# CY8C5888LTI_LP097 register map
File version: 0.1
Registers are 8-bit, read-write, no defined reset value unless marked. A register's access mark holds for its fields unless they carry their own. Offsets are from the block's base; [hi:lo] are bit positions; 'fields as' and 'values as' point back to an identical list.

## BLANK_TOGGLE
Base 0x00000000
0x40006578 BLANK_TOGGLE_CONTROL_REG

## CAM_SEL_REG
Base 0x00000000
0x40006579 CAM_SEL_REG_CONTROL_REG

## TRIG_CNT_RST
Base 0x00000000
0x40006470 TRIG_CNT_RST_CONTROL_REG

## TRG_CNT
Base 0x00000000
0x40006400 TRG_CNT_COUNTER 32-bit — UDB.A0 - Current Counter Value
0x40006420 TRG_CNT_PERIOD 32-bit — UDB.D0 - Assigned Period
0x40006430 TRG_CNT_COMPARE 32-bit — UDB.D1 - Assigned Compare Value
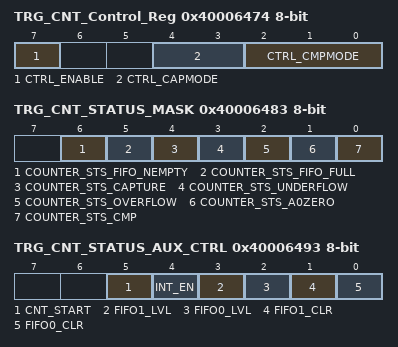
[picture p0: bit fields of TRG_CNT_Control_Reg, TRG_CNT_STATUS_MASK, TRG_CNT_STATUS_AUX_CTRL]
0x40006474 TRG_CNT_Control_Reg — UDB Control Register - Assigned Control Register Value
  [7] CTRL_ENABLE — Enable Counter
  [4:3] CTRL_CAPMODE — Capture mode
  [2:0] CTRL_CMPMODE — Compare mode
0x40006483 TRG_CNT_STATUS_MASK — UDB Status bits Interrupt Mask Enable Register
  [6] COUNTER_STS_FIFO_NEMPTY — FIFO Not Empty Status
  [5] COUNTER_STS_FIFO_FULL — FIFO Full Status
  [4] COUNTER_STS_CAPTURE — Capture Status
  [3] COUNTER_STS_UNDERFLOW — Underflow status
  [2] COUNTER_STS_OVERFLOW — Overflow status
  [1] COUNTER_STS_A0ZERO — A0 Zero ouput status
  [0] COUNTER_STS_CMP — Compare output status
0x40006493 TRG_CNT_STATUS_AUX_CTRL — UDB Auxilliary Control Register
  [5] CNT_START — FIFO0 clear
    0=E_CNT_START0 (Disable counter); 1=E_CNT_START1 (Enable counter)
  [4] INT_EN
    0=E_INT_EN0 (Interrupt disabled); 1=E_INT_EN1 (Interrupt enabled)
  [3] FIFO1_LVL — FIFO level
    0=E_FIFO_LVL_0 (FIFO LVL: input mode: FIFO not full; output mode: FIFO not empty); 1=E_FIFO_LVL_1 (FIFO LVL: input mode: FIFO at least 1/2 empty; output mode: FIFO at least 1/2 full)
  [2] FIFO0_LVL — FIFO level
    values as FIFO1_LVL
  [1] FIFO1_CLR — FIFO1 clear
    0=E_FIFO_CLR_0 (Normal FIFO operation); 1=E_FIFO_CLR_1 (Clear FIFO state)
  [0] FIFO0_CLR — FIFO0 clear
    values as FIFO1_CLR

## STAGE_TRIG
Base 0x00000000
0x40006404 STAGE_TRIG_COUNTER 32-bit — UDB.A0 - Current Counter Value
0x40006424 STAGE_TRIG_PERIOD 32-bit — UDB.D0 - Assigned Period
0x40006434 STAGE_TRIG_COMPARE 32-bit — UDB.D1 - Assigned Compare Value
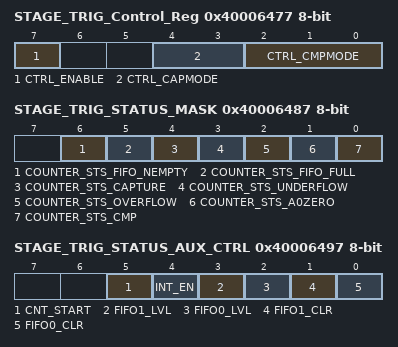
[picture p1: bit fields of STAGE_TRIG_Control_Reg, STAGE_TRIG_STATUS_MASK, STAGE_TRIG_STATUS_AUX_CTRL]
0x40006477 STAGE_TRIG_Control_Reg — UDB Control Register - Assigned Control Register Value
  [7] CTRL_ENABLE — Enable Counter
  [4:3] CTRL_CAPMODE — Capture mode
  [2:0] CTRL_CMPMODE — Compare mode
0x40006487 STAGE_TRIG_STATUS_MASK — UDB Status bits Interrupt Mask Enable Register
  [6] COUNTER_STS_FIFO_NEMPTY — FIFO Not Empty Status
  [5] COUNTER_STS_FIFO_FULL — FIFO Full Status
  [4] COUNTER_STS_CAPTURE — Capture Status
  [3] COUNTER_STS_UNDERFLOW — Underflow status
  [2] COUNTER_STS_OVERFLOW — Overflow status
  [1] COUNTER_STS_A0ZERO — A0 Zero ouput status
  [0] COUNTER_STS_CMP — Compare output status
0x40006497 STAGE_TRIG_STATUS_AUX_CTRL — UDB Auxilliary Control Register
  [5] CNT_START — FIFO0 clear
    0=E_CNT_START0 (Disable counter); 1=E_CNT_START1 (Enable counter)
  [4] INT_EN
    0=E_INT_EN0 (Interrupt disabled); 1=E_INT_EN1 (Interrupt enabled)
  [3] FIFO1_LVL — FIFO level
    0=E_FIFO_LVL_0 (FIFO LVL: input mode: FIFO not full; output mode: FIFO not empty); 1=E_FIFO_LVL_1 (FIFO LVL: input mode: FIFO at least 1/2 empty; output mode: FIFO at least 1/2 full)
  [2] FIFO0_LVL — FIFO level
    values as FIFO1_LVL
  [1] FIFO1_CLR — FIFO1 clear
    0=E_FIFO_CLR_0 (Normal FIFO operation); 1=E_FIFO_CLR_1 (Clear FIFO state)
  [0] FIFO0_CLR — FIFO0 clear
    values as FIFO1_CLR

## STAGE_REG
Base 0x00000000
0x40006475 STAGE_REG_CONTROL_REG

## SLM_WAIT
Base 0x00000000
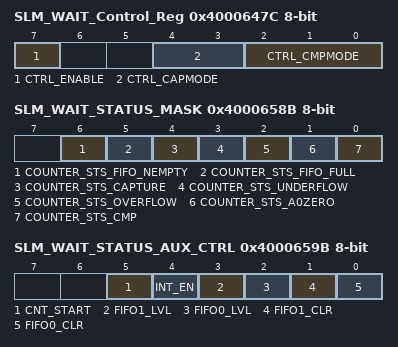
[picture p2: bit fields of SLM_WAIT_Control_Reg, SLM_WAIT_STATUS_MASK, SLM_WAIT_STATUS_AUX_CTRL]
0x4000647C SLM_WAIT_Control_Reg — UDB Control Register - Assigned Control Register Value
  [7] CTRL_ENABLE — Enable Counter
  [4:3] CTRL_CAPMODE — Capture mode
  [2:0] CTRL_CMPMODE — Compare mode
0x40006508 SLM_WAIT_COUNTER 32-bit — UDB.A0 - Current Counter Value
0x40006528 SLM_WAIT_PERIOD 32-bit — UDB.D0 - Assigned Period
0x40006538 SLM_WAIT_COMPARE 32-bit — UDB.D1 - Assigned Compare Value
0x4000658B SLM_WAIT_STATUS_MASK — UDB Status bits Interrupt Mask Enable Register
  [6] COUNTER_STS_FIFO_NEMPTY — FIFO Not Empty Status
  [5] COUNTER_STS_FIFO_FULL — FIFO Full Status
  [4] COUNTER_STS_CAPTURE — Capture Status
  [3] COUNTER_STS_UNDERFLOW — Underflow status
  [2] COUNTER_STS_OVERFLOW — Overflow status
  [1] COUNTER_STS_A0ZERO — A0 Zero ouput status
  [0] COUNTER_STS_CMP — Compare output status
0x4000659B SLM_WAIT_STATUS_AUX_CTRL — UDB Auxilliary Control Register
  [5] CNT_START — FIFO0 clear
    0=E_CNT_START0 (Disable counter); 1=E_CNT_START1 (Enable counter)
  [4] INT_EN
    0=E_INT_EN0 (Interrupt disabled); 1=E_INT_EN1 (Interrupt enabled)
  [3] FIFO1_LVL — FIFO level
    0=E_FIFO_LVL_0 (FIFO LVL: input mode: FIFO not full; output mode: FIFO not empty); 1=E_FIFO_LVL_1 (FIFO LVL: input mode: FIFO at least 1/2 empty; output mode: FIFO at least 1/2 full)
  [2] FIFO0_LVL — FIFO level
    values as FIFO1_LVL
  [1] FIFO1_CLR — FIFO1 clear
    0=E_FIFO_CLR_0 (Normal FIFO operation); 1=E_FIFO_CLR_1 (Clear FIFO state)
  [0] FIFO0_CLR — FIFO0 clear
    values as FIFO1_CLR

## ENBL_TRIG_ISR
Base 0x00000000
0x40006478 ENBL_TRIG_ISR_CONTROL_REG
